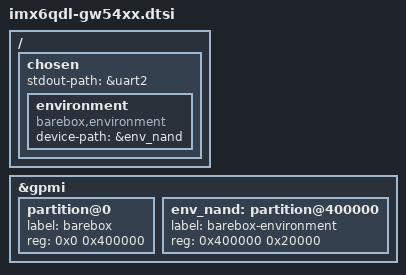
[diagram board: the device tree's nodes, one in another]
/*
 * Copyright 2013 Gateworks Corporation
 *
 * The code contained herein is licensed under the GNU General Public
 * License. You may obtain a copy of the GNU General Public License
 * Version 2 or later at the following locations:
 *
 * http://www.opensource.org/licenses/gpl-license.html
 * http://www.gnu.org/copyleft/gpl.html
 */

 #include <arm/nxp/imx/imx6qdl-gw54xx.dtsi>

 / {
	chosen {
		stdout-path = &uart2;

		environment {
			compatible = "barebox,environment";
			device-path = &env_nand;
		};
	};
};

&gpmi {
	#address-cells = <1>;
	#size-cells = <1>;

	partition@0 {
		label = "barebox";
		reg = <0x0 0x400000>;
	};

	env_nand: partition@400000 {
		label = "barebox-environment";
		reg = <0x400000 0x20000>;
	};
};
